# STM32WB55x register map
File version: 1.0
CPU: CM4 r0p1, little endian, 4 interrupt priority bits
Registers are 32-bit, read-write, reset 0x0 unless marked. A register's access mark holds for its fields unless they carry their own. Offsets are from the block's base; [hi:lo] are bit positions; {n}, {i} and the like mark numbered series.

## GPIOH
Base 0x48001C00
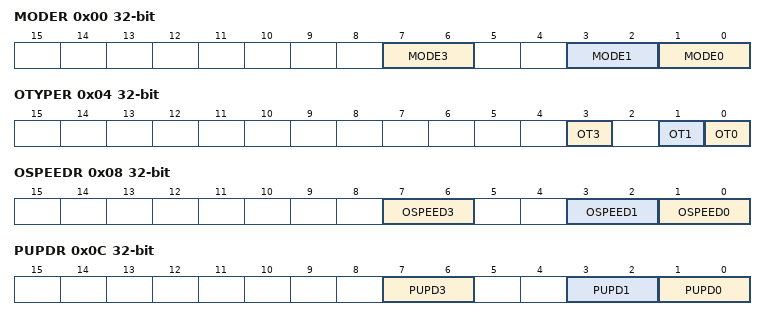
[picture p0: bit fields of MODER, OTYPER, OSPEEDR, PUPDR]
0x00 MODER
  [7:6] MODE3, [3:2] MODE1, [1:0] MODE0
0x04 OTYPER
  [3] OT3, [1] OT1, [0] OT0
0x08 OSPEEDR
  [7:6] OSPEED3, [3:2] OSPEED1, [1:0] OSPEED0
0x0C PUPDR
  [7:6] PUPD3, [3:2] PUPD1, [1:0] PUPD0
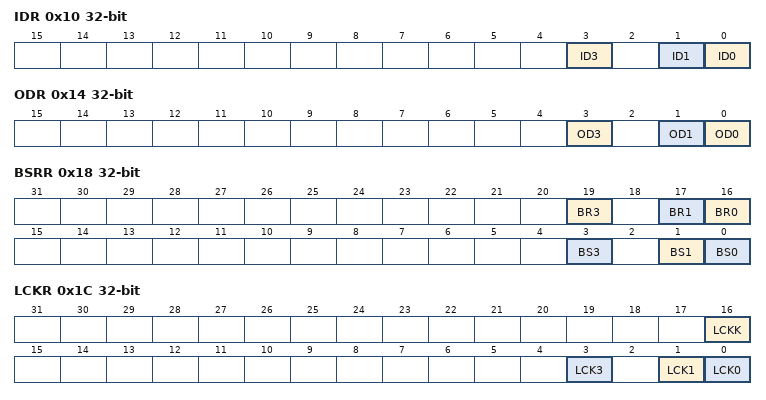
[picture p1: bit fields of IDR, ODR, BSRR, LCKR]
0x10 IDR
  [3] ID3, [1] ID1, [0] ID0
0x14 ODR
  [3] OD3, [1] OD1, [0] OD0
0x18 BSRR
  [19] BR3, [17] BR1, [16] BR0, [3] BS3, [1] BS1, [0] BS0
0x1C LCKR
  [16] LCKK, [3] LCK3, [1] LCK1, [0] LCK0
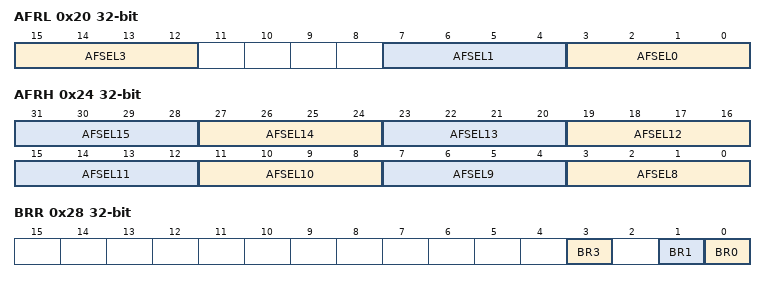
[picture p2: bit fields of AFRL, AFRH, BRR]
0x20 AFRL
  [15:12] AFSEL3, [7:4] AFSEL1, [3:0] AFSEL0
0x24 AFRH
  [4n-29:4n-32] AFSEL{n} (n=8..15)
0x28 BRR
  [3] BR3, [1] BR1, [0] BR0

## TIM1
Base 0x40012C00
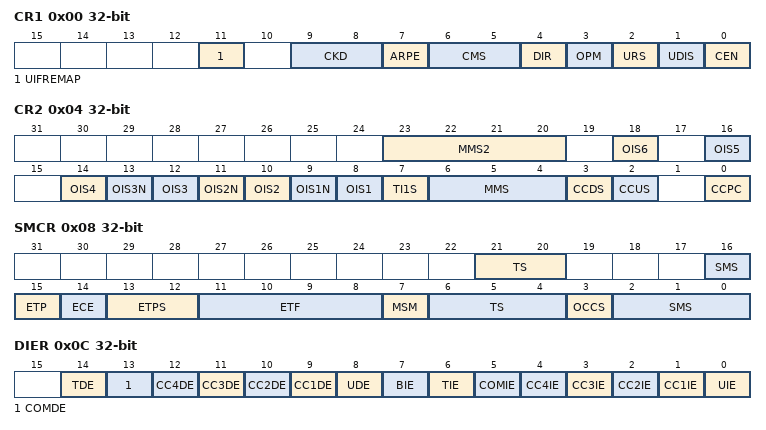
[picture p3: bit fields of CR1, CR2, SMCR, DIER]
0x00 CR1
  [11] UIFREMAP, [9:8] CKD, [7] ARPE, [6:5] CMS, [4] DIR, [3] OPM, [2] URS, [1] UDIS, [0] CEN
0x04 CR2
  [23:20] MMS2, [2n+6] OIS{n} (n=1..6), [13] OIS3N, [11] OIS2N, [9] OIS1N, [7] TI1S, [6:4] MMS, [3] CCDS, [2] CCUS, [0] CCPC
0x08 SMCR
  [21:20] TS, [16] SMS, [15] ETP, [14] ECE, [13:12] ETPS, [11:8] ETF, [7] MSM, [6:4] TS, [3] OCCS, [2:0] SMS
0x0C DIER
  [14] TDE, [13] COMDE, [n+8] CC{n}DE (n=1..4), [8] UDE, [7] BIE, [6] TIE, [5] COMIE, [n] CC{n}IE (n=1..4), [0] UIE
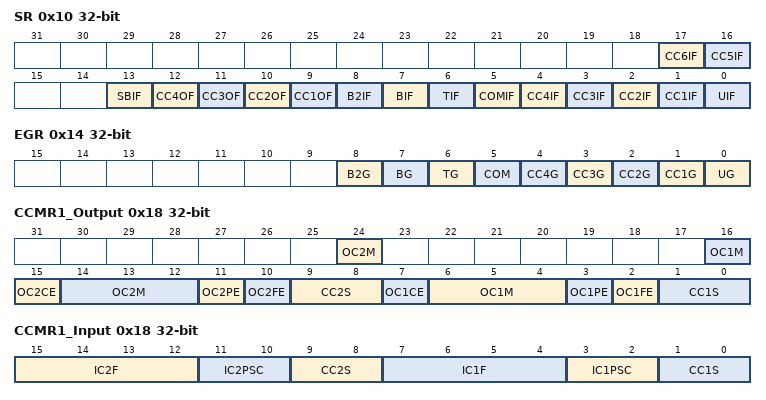
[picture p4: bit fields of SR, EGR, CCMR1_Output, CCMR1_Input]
0x10 SR
  [17] CC6IF, [16] CC5IF, [13] SBIF, [n+8] CC{n}OF (n=1..4), [8] B2IF, [7] BIF, [6] TIF, [5] COMIF, [n] CC{n}IF (n=1..4), [0] UIF
0x14 EGR
  [8] B2G, [7] BG, [6] TG, [5] COM, [n] CC{n}G (n=1..4), [0] UG
0x18 CCMR1_Output
  [24] OC2M, [16] OC1M, [15] OC2CE, [14:12] OC2M, [11] OC2PE, [10] OC2FE, [9:8] CC2S, [7] OC1CE, [6:4] OC1M, [3] OC1PE, [2] OC1FE, [1:0] CC1S
0x18 CCMR1_Input
  [15:12] IC2F, [11:10] IC2PSC, [9:8] CC2S, [7:4] IC1F, [3:2] IC1PSC, [1:0] CC1S
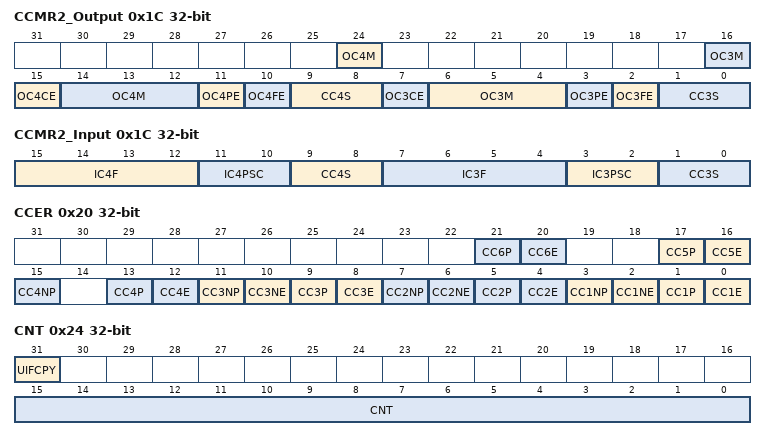
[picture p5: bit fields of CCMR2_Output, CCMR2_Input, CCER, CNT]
0x1C CCMR2_Output
  [24] OC4M, [16] OC3M, [15] OC4CE, [14:12] OC4M, [11] OC4PE, [10] OC4FE, [9:8] CC4S, [7] OC3CE, [6:4] OC3M, [3] OC3PE, [2] OC3FE, [1:0] CC3S
0x1C CCMR2_Input
  [15:12] IC4F, [11:10] IC4PSC, [9:8] CC4S, [7:4] IC3F, [3:2] IC3PSC, [1:0] CC3S
0x20 CCER
  [4n-3] CC{n}P (n=1..6), [4n-4] CC{n}E (n=1..6), [4n-1] CC{n}NP (n=1..4), [10] CC3NE, [6] CC2NE, [2] CC1NE
0x24 CNT
  [31] UIFCPY, [15:0] CNT
0x28 PSC
  [15:0] PSC
0x2C ARR
  [15:0] ARR
0x30 RCR
  [15:0] REP
{0x30+4i} CCR{i} (i=1..4)
  [15:0] CCR{i}
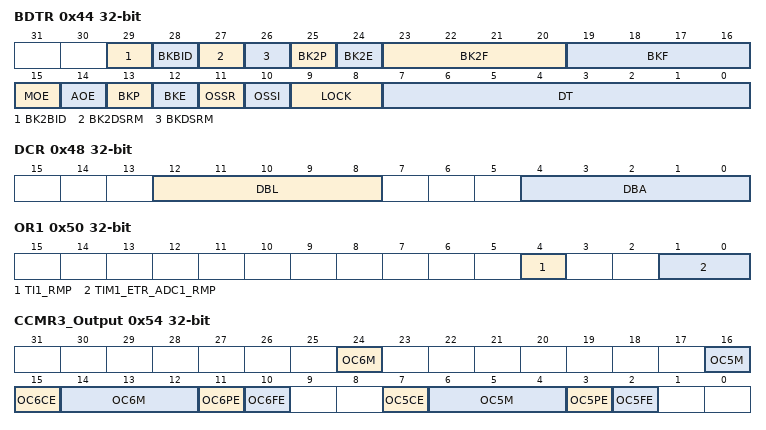
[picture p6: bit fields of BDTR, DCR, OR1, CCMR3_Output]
0x44 BDTR
  [29] BK2BID, [28] BKBID, [27] BK2DSRM, [26] BKDSRM, [25] BK2P, [24] BK2E, [23:20] BK2F, [19:16] BKF, [15] MOE, [14] AOE, [13] BKP, [12] BKE, [11] OSSR, [10] OSSI, [9:8] LOCK, [7:0] DT
0x48 DCR
  [12:8] DBL, [4:0] DBA
0x4C DMAR
  [31:0] DMAB
0x50 OR1
  [4] TI1_RMP, [1:0] TIM1_ETR_ADC1_RMP
0x54 CCMR3_Output
  [24] OC6M, [16] OC5M, [15] OC6CE, [14:12] OC6M, [11] OC6PE, [10] OC6FE, [7] OC5CE, [6:4] OC5M, [3] OC5PE, [2] OC5FE
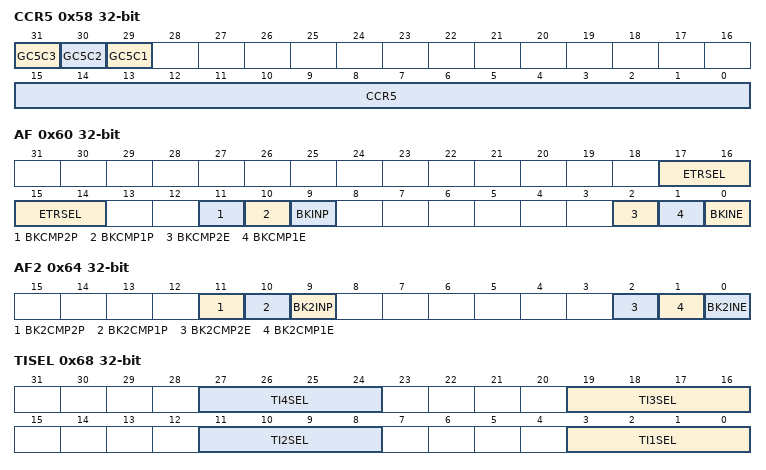
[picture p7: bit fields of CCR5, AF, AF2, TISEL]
0x58 CCR5
  [31] GC5C3, [30] GC5C2, [29] GC5C1, [15:0] CCR5
0x5C CCR6
  [15:0] CCR6
0x60 AF
  [17:14] ETRSEL, [11] BKCMP2P, [10] BKCMP1P, [9] BKINP, [2] BKCMP2E, [1] BKCMP1E, [0] BKINE
0x64 AF2
  [11] BK2CMP2P, [10] BK2CMP1P, [9] BK2INP, [2] BK2CMP2E, [1] BK2CMP1E, [0] BK2INE
0x68 TISEL
  [8n-5:8n-8] TI{n}SEL (n=1..4)

## TIM2
Base 0x40000000
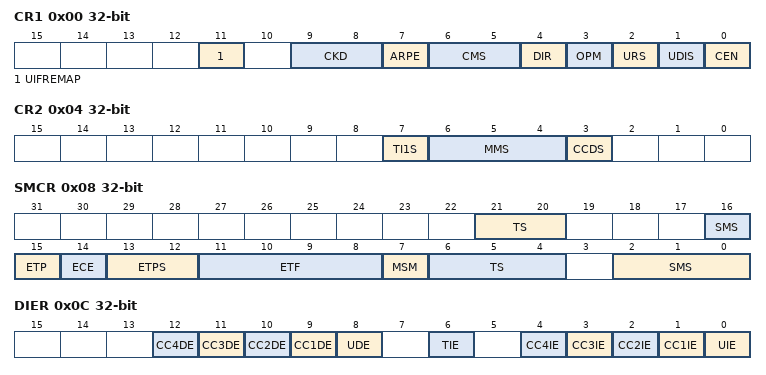
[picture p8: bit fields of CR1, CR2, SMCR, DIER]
0x00 CR1
  [11] UIFREMAP, [9:8] CKD, [7] ARPE, [6:5] CMS, [4] DIR, [3] OPM, [2] URS, [1] UDIS, [0] CEN
0x04 CR2
  [7] TI1S, [6:4] MMS, [3] CCDS
0x08 SMCR
  [21:20] TS, [16] SMS, [15] ETP, [14] ECE, [13:12] ETPS, [11:8] ETF, [7] MSM, [6:4] TS, [2:0] SMS
0x0C DIER
  [n+8] CC{n}DE (n=1..4), [8] UDE, [6] TIE, [n] CC{n}IE (n=1..4), [0] UIE
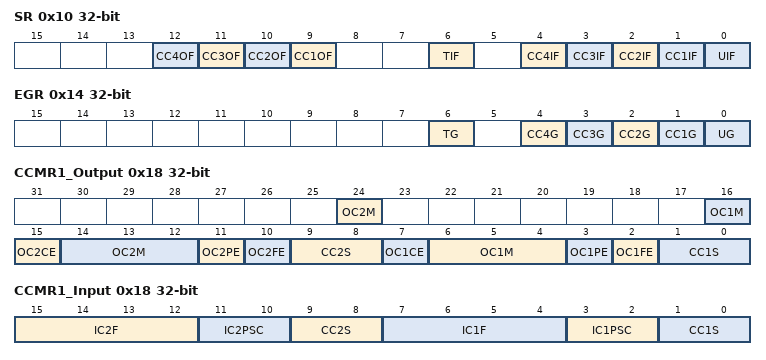
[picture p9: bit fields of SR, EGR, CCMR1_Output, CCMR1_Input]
0x10 SR
  [n+8] CC{n}OF (n=1..4), [6] TIF, [n] CC{n}IF (n=1..4), [0] UIF
0x14 EGR
  [6] TG, [n] CC{n}G (n=1..4), [0] UG
0x18 CCMR1_Output
  [24] OC2M, [16] OC1M, [15] OC2CE, [14:12] OC2M, [11] OC2PE, [10] OC2FE, [9:8] CC2S, [7] OC1CE, [6:4] OC1M, [3] OC1PE, [2] OC1FE, [1:0] CC1S
0x18 CCMR1_Input
  [15:12] IC2F, [11:10] IC2PSC, [9:8] CC2S, [7:4] IC1F, [3:2] IC1PSC, [1:0] CC1S
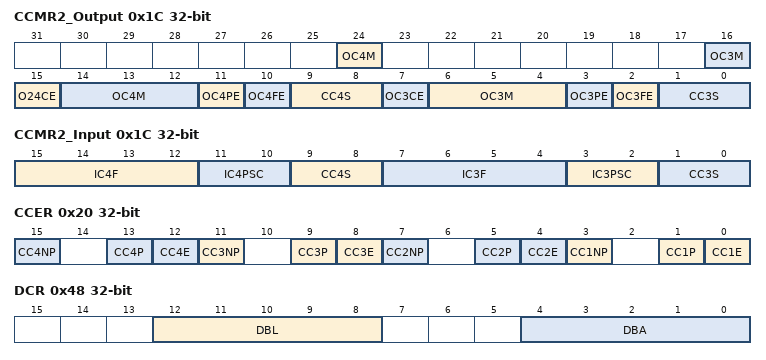
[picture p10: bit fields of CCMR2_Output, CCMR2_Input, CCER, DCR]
0x1C CCMR2_Output
  [24] OC4M, [16] OC3M, [15] O24CE, [14:12] OC4M, [11] OC4PE, [10] OC4FE, [9:8] CC4S, [7] OC3CE, [6:4] OC3M, [3] OC3PE, [2] OC3FE, [1:0] CC3S
0x1C CCMR2_Input
  [15:12] IC4F, [11:10] IC4PSC, [9:8] CC4S, [7:4] IC3F, [3:2] IC3PSC, [1:0] CC3S
0x20 CCER
  [4n-1] CC{n}NP (n=1..4), [4n-3] CC{n}P (n=1..4), [4n-4] CC{n}E (n=1..4)
0x24 CNT
0x28 PSC
  [15:0] PSC
0x2C ARR
{0x30+4i} CCR{i} (i=1..4)
0x48 DCR
  [12:8] DBL, [4:0] DBA
0x4C DMAR
  [15:0] DMAB
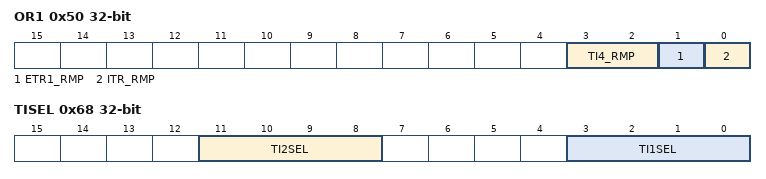
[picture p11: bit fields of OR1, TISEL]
0x50 OR1
  [3:2] TI4_RMP, [1] ETR1_RMP, [0] ITR_RMP
0x60 AF1
  [17:14] ETRSEL
0x68 TISEL
  [11:8] TI2SEL, [3:0] TI1SEL
